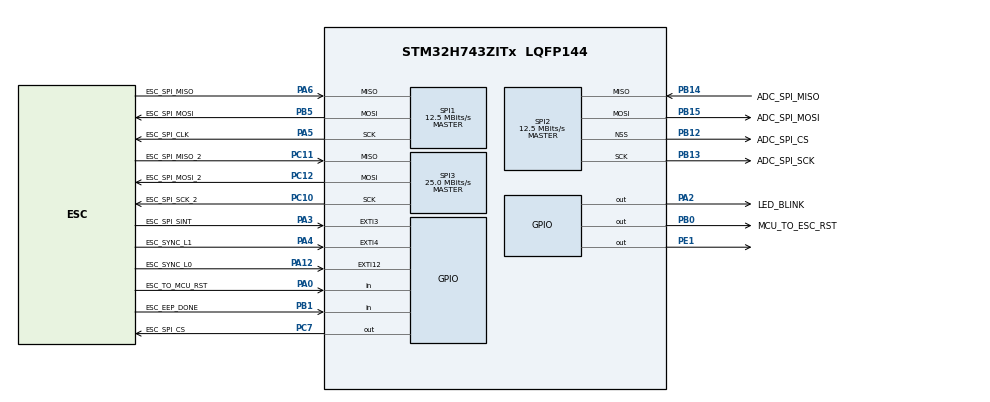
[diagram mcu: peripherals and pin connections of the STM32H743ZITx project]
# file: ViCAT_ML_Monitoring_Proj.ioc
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CORTEX_M7.default_mode_Activation=1
Mcu.Family=STM32H7
Mcu.Name=STM32H743ZITx
Mcu.Package=LQFP144
NVIC.EXTI15_10_IRQn=true\:0\:0\:false\:false\:true\:true\:true\:true
NVIC.EXTI3_IRQn=true\:0\:0\:false\:false\:true\:true\:true\:true
NVIC.EXTI4_IRQn=true\:0\:0\:false\:false\:true\:true\:true\:true
NVIC.PriorityGroup=NVIC_PRIORITYGROUP_4
NVIC.SPI2_IRQn=true\:0\:0\:false\:false\:true\:true\:true\:true
NVIC.TIM16_IRQn=true\:0\:0\:false\:false\:true\:true\:true\:true
PA0.GPIO_Label=ESC_TO_MCU_RST
PA0.Signal=GPIO_Input
PA12.GPIO_Label=ESC_SYNC_L0
PA12.GPIO_ModeDefaultEXTI=GPIO_MODE_IT_FALLING
PA12.GPIO_PuPd=GPIO_PULLUP
PA12.Signal=GPXTI12
PA13\ (JTMS/SWDIO).Mode=Serial_Wire
PA13\ (JTMS/SWDIO).Signal=DEBUG_JTMS-SWDIO
PA14\ (JTCK/SWCLK).Mode=Serial_Wire
PA14\ (JTCK/SWCLK).Signal=DEBUG_JTCK-SWCLK
PA2.GPIO_Label=LED_BLINK
PA2.GPIO_PuPd=GPIO_PULLDOWN
PA2.Signal=GPIO_Output
PA3.GPIO_Label=ESC_SPI_SINT
PA3.GPIO_ModeDefaultEXTI=GPIO_MODE_IT_FALLING
PA3.GPIO_PuPd=GPIO_PULLUP
PA3.Signal=GPXTI3
PA4.GPIO_Label=ESC_SYNC_L1
PA4.GPIO_ModeDefaultEXTI=GPIO_MODE_IT_FALLING
PA4.GPIO_PuPd=GPIO_PULLUP
PA4.Signal=GPXTI4
PA5.GPIO_Label=ESC_SPI_CLK
PA5.GPIO_PuPd=GPIO_NOPULL
PA5.GPIO_Speed=GPIO_SPEED_FREQ_HIGH
PA5.Mode=Full_Duplex_Master
PA5.Signal=SPI1_SCK
PA6.GPIO_Label=ESC_SPI_MISO
PA6.GPIO_Speed=GPIO_SPEED_FREQ_HIGH
PA6.Mode=Full_Duplex_Master
PA6.Signal=SPI1_MISO
PB0.GPIO_Label=MCU_TO_ESC_RST
PB0.GPIO_PuPd=GPIO_NOPULL
PB0.GPIO_Speed=GPIO_SPEED_FREQ_MEDIUM
PB0.Signal=GPIO_Output
PB1.GPIO_Label=ESC_EEP_DONE
PB1.GPIO_PuPd=GPIO_PULLDOWN
PB1.Signal=GPIO_Input
PB12.GPIO_Label=ADC_SPI_CS
PB12.GPIO_Speed=GPIO_SPEED_FREQ_LOW
PB12.Mode=NSS_Signal_Hard_Output
PB12.Signal=SPI2_NSS
PB13.GPIO_Label=ADC_SPI_SCK
PB13.GPIO_PuPd=GPIO_PULLUP
PB13.Mode=Full_Duplex_Master
PB13.Signal=SPI2_SCK
PB14.GPIO_Label=ADC_SPI_MISO
PB14.Mode=Full_Duplex_Master
PB14.Signal=SPI2_MISO
PB15.GPIO_Label=ADC_SPI_MOSI
PB15.Mode=Full_Duplex_Master
PB15.Signal=SPI2_MOSI
PB5.GPIO_Label=ESC_SPI_MOSI
PB5.GPIO_PuPd=GPIO_NOPULL
PB5.GPIO_Speed=GPIO_SPEED_FREQ_HIGH
PB5.Mode=Full_Duplex_Master
PB5.Signal=SPI1_MOSI
PC10.GPIO_Label=ESC_SPI_SCK_2
PC10.GPIO_Speed=GPIO_SPEED_FREQ_HIGH
PC10.Mode=Full_Duplex_Master
PC10.Signal=SPI3_SCK
PC11.GPIO_Label=ESC_SPI_MISO_2
PC11.GPIO_Speed=GPIO_SPEED_FREQ_HIGH
PC11.Mode=Full_Duplex_Master
PC11.Signal=SPI3_MISO
PC12.GPIO_Label=ESC_SPI_MOSI_2
PC12.GPIO_PuPd=GPIO_PULLUP
PC12.GPIO_Speed=GPIO_SPEED_FREQ_HIGH
PC12.Mode=Full_Duplex_Master
PC12.Signal=SPI3_MOSI
PC14-OSC32_IN\ (OSC32_IN).Mode=LSE-External-Oscillator
PC14-OSC32_IN\ (OSC32_IN).Signal=RCC_OSC32_IN
PC15-OSC32_OUT\ (OSC32_OUT).Mode=LSE-External-Oscillator
PC15-OSC32_OUT\ (OSC32_OUT).Signal=RCC_OSC32_OUT
PC7.GPIO_Label=ESC_SPI_CS
PC7.GPIO_PuPd=GPIO_PULLDOWN
PC7.GPIO_Speed=GPIO_SPEED_FREQ_VERY_HIGH
PC7.Signal=GPIO_Output
PE1.Signal=GPIO_Output
PH0-OSC_IN\ (PH0).GPIO_Label=MCO
PH0-OSC_IN\ (PH0).Mode=HSE-External-Oscillator
PH0-OSC_IN\ (PH0).Signal=RCC_OSC_IN
PH1-OSC_OUT\ (PH1).Mode=HSE-External-Oscillator
PH1-OSC_OUT\ (PH1).Signal=RCC_OSC_OUT
ProjectManager.HeapSize=0x200
ProjectManager.StackSize=0x400
ProjectManager.TargetToolchain=STM32CubeIDE
RCC.ADCFreq_Value=50390625
RCC.APB1Freq_Value=100000000
RCC.APB2Freq_Value=100000000
RCC.APB3Freq_Value=100000000
RCC.APB4Freq_Value=100000000
RCC.CortexFreq_Value=100000000
RCC.DIVM1=3
RCC.DIVN1=24
RCC.HCLKFreq_Value=100000000
RCC.PLL2FRACN=0
RCC.PLL3FRACN=0
RCC.PLLFRACN=0
RCC.PLLSourceVirtual=RCC_PLLSOURCE_HSE
RCC.SYSCLKFreq_VALUE=100000000
RCC.SYSCLKSource=RCC_SYSCLKSOURCE_PLLCLK
RCC.USBFreq_Value=100000000
SPI1.BaudRatePrescaler=SPI_BAUDRATEPRESCALER_8
SPI1.CLKPhase=SPI_PHASE_2EDGE
SPI1.CLKPolarity=SPI_POLARITY_HIGH
SPI1.CalculateBaudRate=12.5 MBits/s
SPI1.DataSize=SPI_DATASIZE_8BIT
SPI1.Direction=SPI_DIRECTION_2LINES
SPI1.Mode=SPI_MODE_MASTER
SPI1.VirtualType=VM_MASTER
SPI2.BaudRatePrescaler=SPI_BAUDRATEPRESCALER_8
SPI2.CLKPhase=SPI_PHASE_2EDGE
SPI2.CLKPolarity=SPI_POLARITY_HIGH
SPI2.CalculateBaudRate=12.5 MBits/s
SPI2.DataSize=SPI_DATASIZE_8BIT
SPI2.Direction=SPI_DIRECTION_2LINES
SPI2.Mode=SPI_MODE_MASTER
SPI2.VirtualNSS=VM_NSSHARD
SPI2.VirtualType=VM_MASTER
SPI3.BaudRatePrescaler=SPI_BAUDRATEPRESCALER_4
SPI3.CLKPhase=SPI_PHASE_2EDGE
SPI3.CLKPolarity=SPI_POLARITY_HIGH
SPI3.CalculateBaudRate=25.0 MBits/s
SPI3.DataSize=SPI_DATASIZE_8BIT
SPI3.Direction=SPI_DIRECTION_2LINES
SPI3.Mode=SPI_MODE_MASTER
SPI3.VirtualType=VM_MASTER
TIM16.Period=999
TIM16.Prescaler=99
TIM6.Period=999
TIM6.Prescaler=49
VP_MEMORYMAP_VS_MEMORYMAP.Mode=CurAppReg
VP_TIM16_VS_ClockSourceINT.Mode=Enable_Timer
VP_TIM6_VS_ClockSourceINT.Mode=Enable_Timer
board=custom

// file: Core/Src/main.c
/* USER CODE BEGIN Header */
/**
  ******************************************************************************
  * @file           : main.c
  * @brief          : Main program body
  ******************************************************************************
  * @attention
  *
  * Copyright (c) 2024 STMicroelectronics.
  * All rights reserved.
  *
  * This software is licensed under terms that can be found in the LICENSE file
  * in the root directory of this software component.
  * If no LICENSE file comes with this software, it is provided AS-IS.
  *
  ******************************************************************************
  */
/* USER CODE END Header */
#include "main.h"
#include "memorymap.h"
#include "spi.h"
#include "tim.h"
#include "gpio.h"

/* USER CODE BEGIN Includes */
#include "ViCAT_ML_LSC_Proj.h"
//#include "ViCAT_ML_LSC_ProjObjects.h"
/* USER CODE END Includes */

/* USER CODE BEGIN PD */
#define MAP2LEVEL(x) ((x==0)? GPIO_PIN_RESET: GPIO_PIN_SET)
/* USER CODE END PD */

void SystemClock_Config(void);
static void MPU_Config(void);

int main(void)
{

  /* MPU Configuration--------------------------------------------------------*/
  MPU_Config();

  /* MCU Configuration--------------------------------------------------------*/

  /* Reset of all peripherals, Initializes the Flash interface and the Systick. */
  HAL_Init();

  /* Configure the system clock */
  SystemClock_Config();

  /* Initialize all configured peripherals */
  MX_GPIO_Init();
  MX_SPI1_Init();
  MX_SPI2_Init();
  MX_TIM6_Init();
  MX_TIM16_Init();
  MX_SPI3_Init();

  /* Infinite loop */
  while (1)
  {

    /* USER CODE BEGIN 3 */
	 //HAL_GPIO_TogglePin(GPIOE,GPIO_PIN_1);
	 // HAL_Delay(100);
	 main_initial();
	 //HAL_GPIO_TogglePin(GPIOE,GPIO_PIN_1);
	 //HAL_Delay(100);
  }
  /* USER CODE END 3 */
}

void SystemClock_Config(void)
{
  RCC_OscInitTypeDef RCC_OscInitStruct = {0};
  RCC_ClkInitTypeDef RCC_ClkInitStruct = {0};

  /** Supply configuration update enable
  */
  HAL_PWREx_ConfigSupply(PWR_LDO_SUPPLY);

  /** Configure the main internal regulator output voltage
  */
  __HAL_PWR_VOLTAGESCALING_CONFIG(PWR_REGULATOR_VOLTAGE_SCALE3);

  while(!__HAL_PWR_GET_FLAG(PWR_FLAG_VOSRDY)) {}

  /** Initializes the RCC Oscillators according to the specified parameters
  * in the RCC_OscInitTypeDef structure.
  */
  RCC_OscInitStruct.OscillatorType = RCC_OSCILLATORTYPE_HSE;
  RCC_OscInitStruct.HSEState = RCC_HSE_ON;
  RCC_OscInitStruct.PLL.PLLState = RCC_PLL_ON;
  RCC_OscInitStruct.PLL.PLLSource = RCC_PLLSOURCE_HSE;
  RCC_OscInitStruct.PLL.PLLM = 3;
  RCC_OscInitStruct.PLL.PLLN = 24;
  RCC_OscInitStruct.PLL.PLLP = 2;
  RCC_OscInitStruct.PLL.PLLQ = 2;
  RCC_OscInitStruct.PLL.PLLR = 2;
  RCC_OscInitStruct.PLL.PLLRGE = RCC_PLL1VCIRANGE_3;
  RCC_OscInitStruct.PLL.PLLVCOSEL = RCC_PLL1VCOWIDE;
  RCC_OscInitStruct.PLL.PLLFRACN = 0;
  if (HAL_RCC_OscConfig(&RCC_OscInitStruct) != HAL_OK)
  {
    Error_Handler();
  }

  /** Initializes the CPU, AHB and APB buses clocks
  */
  RCC_ClkInitStruct.ClockType = RCC_CLOCKTYPE_HCLK|RCC_CLOCKTYPE_SYSCLK
                              |RCC_CLOCKTYPE_PCLK1|RCC_CLOCKTYPE_PCLK2
                              |RCC_CLOCKTYPE_D3PCLK1|RCC_CLOCKTYPE_D1PCLK1;
  RCC_ClkInitStruct.SYSCLKSource = RCC_SYSCLKSOURCE_PLLCLK;
  RCC_ClkInitStruct.SYSCLKDivider = RCC_SYSCLK_DIV1;
  RCC_ClkInitStruct.AHBCLKDivider = RCC_HCLK_DIV1;
  RCC_ClkInitStruct.APB3CLKDivider = RCC_APB3_DIV1;
  RCC_ClkInitStruct.APB1CLKDivider = RCC_APB1_DIV1;
  RCC_ClkInitStruct.APB2CLKDivider = RCC_APB2_DIV1;
  RCC_ClkInitStruct.APB4CLKDivider = RCC_APB4_DIV1;

  if (HAL_RCC_ClockConfig(&RCC_ClkInitStruct, FLASH_LATENCY_2) != HAL_OK)
  {
    Error_Handler();
  }
}

/* USER CODE BEGIN 4 */
void process_app(TOBJ7000 *OUT_GENERIC, TOBJ6000 *IN_GENERIC)
{
  /* OUTPUT PROCESSING */
  /* Check bitfield set by master OUT_GEN_Bit1..8 and set LEDs accordingly */
  //XMC_GPIO_SetOutputLevel(P_LED1, MAP2LEVEL(OUT_GENERIC->OUT_GEN_Bit1));
	HAL_GPIO_WritePin(GPIOE, GPIO_PIN_1, MAP2LEVEL(OUT_GENERIC->OUT_GEN_Bit1));
}
/* USER CODE END 4 */

 /* MPU Configuration */

void MPU_Config(void)
{
  MPU_Region_InitTypeDef MPU_InitStruct = {0};

  /* Disables the MPU */
  HAL_MPU_Disable();

  /** Initializes and configures the Region and the memory to be protected
  */
  MPU_InitStruct.Enable = MPU_REGION_ENABLE;
  MPU_InitStruct.Number = MPU_REGION_NUMBER0;
  MPU_InitStruct.BaseAddress = 0x0;
  MPU_InitStruct.Size = MPU_REGION_SIZE_4GB;
  MPU_InitStruct.SubRegionDisable = 0x87;
  MPU_InitStruct.TypeExtField = MPU_TEX_LEVEL0;
  MPU_InitStruct.AccessPermission = MPU_REGION_NO_ACCESS;
  MPU_InitStruct.DisableExec = MPU_INSTRUCTION_ACCESS_DISABLE;
  MPU_InitStruct.IsShareable = MPU_ACCESS_SHAREABLE;
  MPU_InitStruct.IsCacheable = MPU_ACCESS_NOT_CACHEABLE;
  MPU_InitStruct.IsBufferable = MPU_ACCESS_NOT_BUFFERABLE;

  HAL_MPU_ConfigRegion(&MPU_InitStruct);
  /* Enables the MPU */
  HAL_MPU_Enable(MPU_PRIVILEGED_DEFAULT);

}

void Error_Handler(void)
{
  __disable_irq();
  while (1)
  {
  }
}
